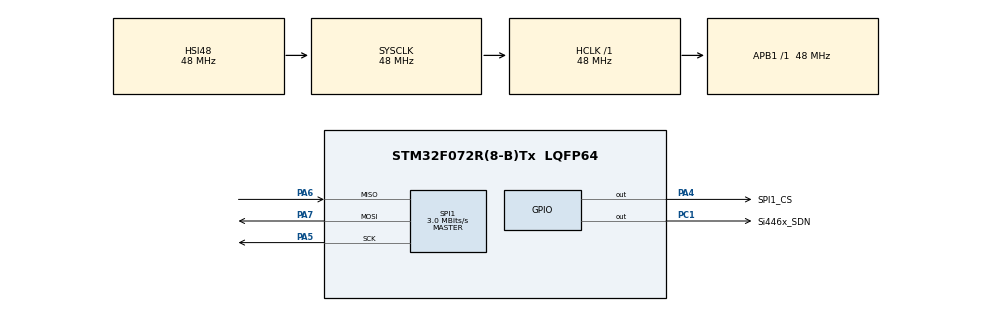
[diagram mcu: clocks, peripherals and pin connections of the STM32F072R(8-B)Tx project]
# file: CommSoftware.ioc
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Mcu.Family=STM32F0
Mcu.Name=STM32F072R(8-B)Tx
Mcu.Package=LQFP64
PA13.GPIO_Label=TMS
PA13.Mode=Serial_Wire
PA13.Signal=SYS_SWDIO
PA14.GPIO_Label=TCK
PA14.Mode=Serial_Wire
PA14.Signal=SYS_SWCLK
PA4.GPIO_Label=SPI1_CS
PA4.Signal=GPIO_Output
PA5.Mode=Full_Duplex_Master
PA5.Signal=SPI1_SCK
PA6.Mode=Full_Duplex_Master
PA6.Signal=SPI1_MISO
PA7.Mode=Full_Duplex_Master
PA7.Signal=SPI1_MOSI
PC1.GPIO_Label=Si446x_SDN
PC1.Signal=GPIO_Output
PC14-OSC32_IN.Mode=LSE-External-Oscillator
PC14-OSC32_IN.Signal=RCC_OSC32_IN
PC15-OSC32_OUT.Mode=LSE-External-Oscillator
PC15-OSC32_OUT.Signal=RCC_OSC32_OUT
PF0-OSC_IN.Mode=HSE-External-Clock-Source
PF0-OSC_IN.Signal=RCC_OSC_IN
PF1-OSC_OUT.Signal=RCC_OSC_OUT
ProjectManager.HeapSize=0x200
ProjectManager.StackSize=0x400
ProjectManager.TargetToolchain=STM32CubeIDE
RCC.AHBFreq_Value=48000000
RCC.APB1Freq_Value=48000000
RCC.APB1TimFreq_Value=48000000
RCC.FLatency-AdvancedSettings=FLASH_LATENCY_1
RCC.HCLKFreq_Value=48000000
RCC.PLLDivider=RCC_PREDIV_DIV2
RCC.PLLMUL=RCC_PLL_MUL12
RCC.PREFETCH_ENABLE-AdvancedSettings=1
RCC.SYSCLKFreq_VALUE=48000000
RCC.SYSCLKSource=RCC_SYSCLKSOURCE_HSI48
SPI1.BaudRatePrescaler=SPI_BAUDRATEPRESCALER_16
SPI1.CalculateBaudRate=3.0 MBits/s
SPI1.DataSize=SPI_DATASIZE_8BIT
SPI1.Direction=SPI_DIRECTION_2LINES
SPI1.Mode=SPI_MODE_MASTER
SPI1.NSSPMode=SPI_NSS_PULSE_DISABLE
SPI1.VirtualType=VM_MASTER
board=NUCLEO-F072RB

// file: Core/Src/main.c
/* USER CODE BEGIN Header */
/**
  ******************************************************************************
  * @file           : main.c
  * @brief          : Main program body
  ******************************************************************************
  * @attention
  *
  * <h2><center>&copy; Copyright (c) 2020 STMicroelectronics.
  * All rights reserved.</center></h2>
  *
  * This software component is licensed by ST under BSD 3-Clause license,
  * the "License"; You may not use this file except in compliance with the
  * License. You may obtain a copy of the License at:
  *                        opensource.org/licenses/BSD-3-Clause
  *
  ******************************************************************************
  */
/* USER CODE END Header */
#include "main.h"

/* USER CODE BEGIN Includes */

#include "Si446x/Si446x.h"

/* USER CODE END Includes */

SPI_HandleTypeDef hspi1;

void SystemClock_Config(void);
static void MX_GPIO_Init(void);
static void MX_SPI1_Init(void);

int main(void)
{

  /* MCU Configuration--------------------------------------------------------*/

  /* Reset of all peripherals, Initializes the Flash interface and the Systick. */
  HAL_Init();

  /* Configure the system clock */
  SystemClock_Config();

  /* Initialize all configured peripherals */
  MX_GPIO_Init();
  MX_SPI1_Init();
  /* USER CODE BEGIN 2 */

  Si446x_init();

  //SPI_PORT->CR1 |= SPI_CR1_SPE; // Enable

  si446x_info_t info;
  Si446x_getInfo(&info);

  uint8_t data[] = {0xaa};

  /* USER CODE END 2 */

  /* Infinite loop */
  while (1)
  {

	  /*
    Si446x_setTxPower(1);
	Si446x_TX(&data, 1, 2, SI446X_STATE_SLEEP);
	HAL_Delay(1000);

	   */
  }
}

void SystemClock_Config(void)
{
  RCC_OscInitTypeDef RCC_OscInitStruct = {0};
  RCC_ClkInitTypeDef RCC_ClkInitStruct = {0};

  /** Initializes the RCC Oscillators according to the specified parameters
  * in the RCC_OscInitTypeDef structure.
  */
  RCC_OscInitStruct.OscillatorType = RCC_OSCILLATORTYPE_HSI48;
  RCC_OscInitStruct.HSI48State = RCC_HSI48_ON;
  RCC_OscInitStruct.PLL.PLLState = RCC_PLL_NONE;
  if (HAL_RCC_OscConfig(&RCC_OscInitStruct) != HAL_OK)
  {
    Error_Handler();
  }
  /** Initializes the CPU, AHB and APB buses clocks
  */
  RCC_ClkInitStruct.ClockType = RCC_CLOCKTYPE_HCLK|RCC_CLOCKTYPE_SYSCLK
                              |RCC_CLOCKTYPE_PCLK1;
  RCC_ClkInitStruct.SYSCLKSource = RCC_SYSCLKSOURCE_HSI48;
  RCC_ClkInitStruct.AHBCLKDivider = RCC_SYSCLK_DIV1;
  RCC_ClkInitStruct.APB1CLKDivider = RCC_HCLK_DIV1;

  if (HAL_RCC_ClockConfig(&RCC_ClkInitStruct, FLASH_LATENCY_1) != HAL_OK)
  {
    Error_Handler();
  }
}

static void MX_SPI1_Init(void)
{

  /* SPI1 parameter configuration*/
  hspi1.Instance = SPI1;
  hspi1.Init.Mode = SPI_MODE_MASTER;
  hspi1.Init.Direction = SPI_DIRECTION_2LINES;
  hspi1.Init.DataSize = SPI_DATASIZE_8BIT;
  hspi1.Init.CLKPolarity = SPI_POLARITY_LOW;
  hspi1.Init.CLKPhase = SPI_PHASE_1EDGE;
  hspi1.Init.NSS = SPI_NSS_SOFT;
  hspi1.Init.BaudRatePrescaler = SPI_BAUDRATEPRESCALER_16;
  hspi1.Init.FirstBit = SPI_FIRSTBIT_MSB;
  hspi1.Init.TIMode = SPI_TIMODE_DISABLE;
  hspi1.Init.CRCCalculation = SPI_CRCCALCULATION_DISABLE;
  hspi1.Init.CRCPolynomial = 7;
  hspi1.Init.CRCLength = SPI_CRC_LENGTH_DATASIZE;
  hspi1.Init.NSSPMode = SPI_NSS_PULSE_DISABLE;
  if (HAL_SPI_Init(&hspi1) != HAL_OK)
  {
    Error_Handler();
  }

}

static void MX_GPIO_Init(void)
{
  GPIO_InitTypeDef GPIO_InitStruct = {0};

  /* GPIO Ports Clock Enable */
  __HAL_RCC_GPIOC_CLK_ENABLE();
  __HAL_RCC_GPIOF_CLK_ENABLE();
  __HAL_RCC_GPIOA_CLK_ENABLE();

  /*Configure GPIO pin Output Level */
  HAL_GPIO_WritePin(Si446x_SDN_GPIO_Port, Si446x_SDN_Pin, GPIO_PIN_RESET);

  /*Configure GPIO pin Output Level */
  HAL_GPIO_WritePin(SPI1_CS_GPIO_Port, SPI1_CS_Pin, GPIO_PIN_RESET);

  /*Configure GPIO pin : Si446x_SDN_Pin */
  GPIO_InitStruct.Pin = Si446x_SDN_Pin;
  GPIO_InitStruct.Mode = GPIO_MODE_OUTPUT_PP;
  GPIO_InitStruct.Pull = GPIO_NOPULL;
  GPIO_InitStruct.Speed = GPIO_SPEED_FREQ_LOW;
  HAL_GPIO_Init(Si446x_SDN_GPIO_Port, &GPIO_InitStruct);

  /*Configure GPIO pin : SPI1_CS_Pin */
  GPIO_InitStruct.Pin = SPI1_CS_Pin;
  GPIO_InitStruct.Mode = GPIO_MODE_OUTPUT_PP;
  GPIO_InitStruct.Pull = GPIO_NOPULL;
  GPIO_InitStruct.Speed = GPIO_SPEED_FREQ_LOW;
  HAL_GPIO_Init(SPI1_CS_GPIO_Port, &GPIO_InitStruct);

}

void Error_Handler(void)
{
}

/************************ (C) COPYRIGHT STMicroelectronics *****END OF FILE****/
